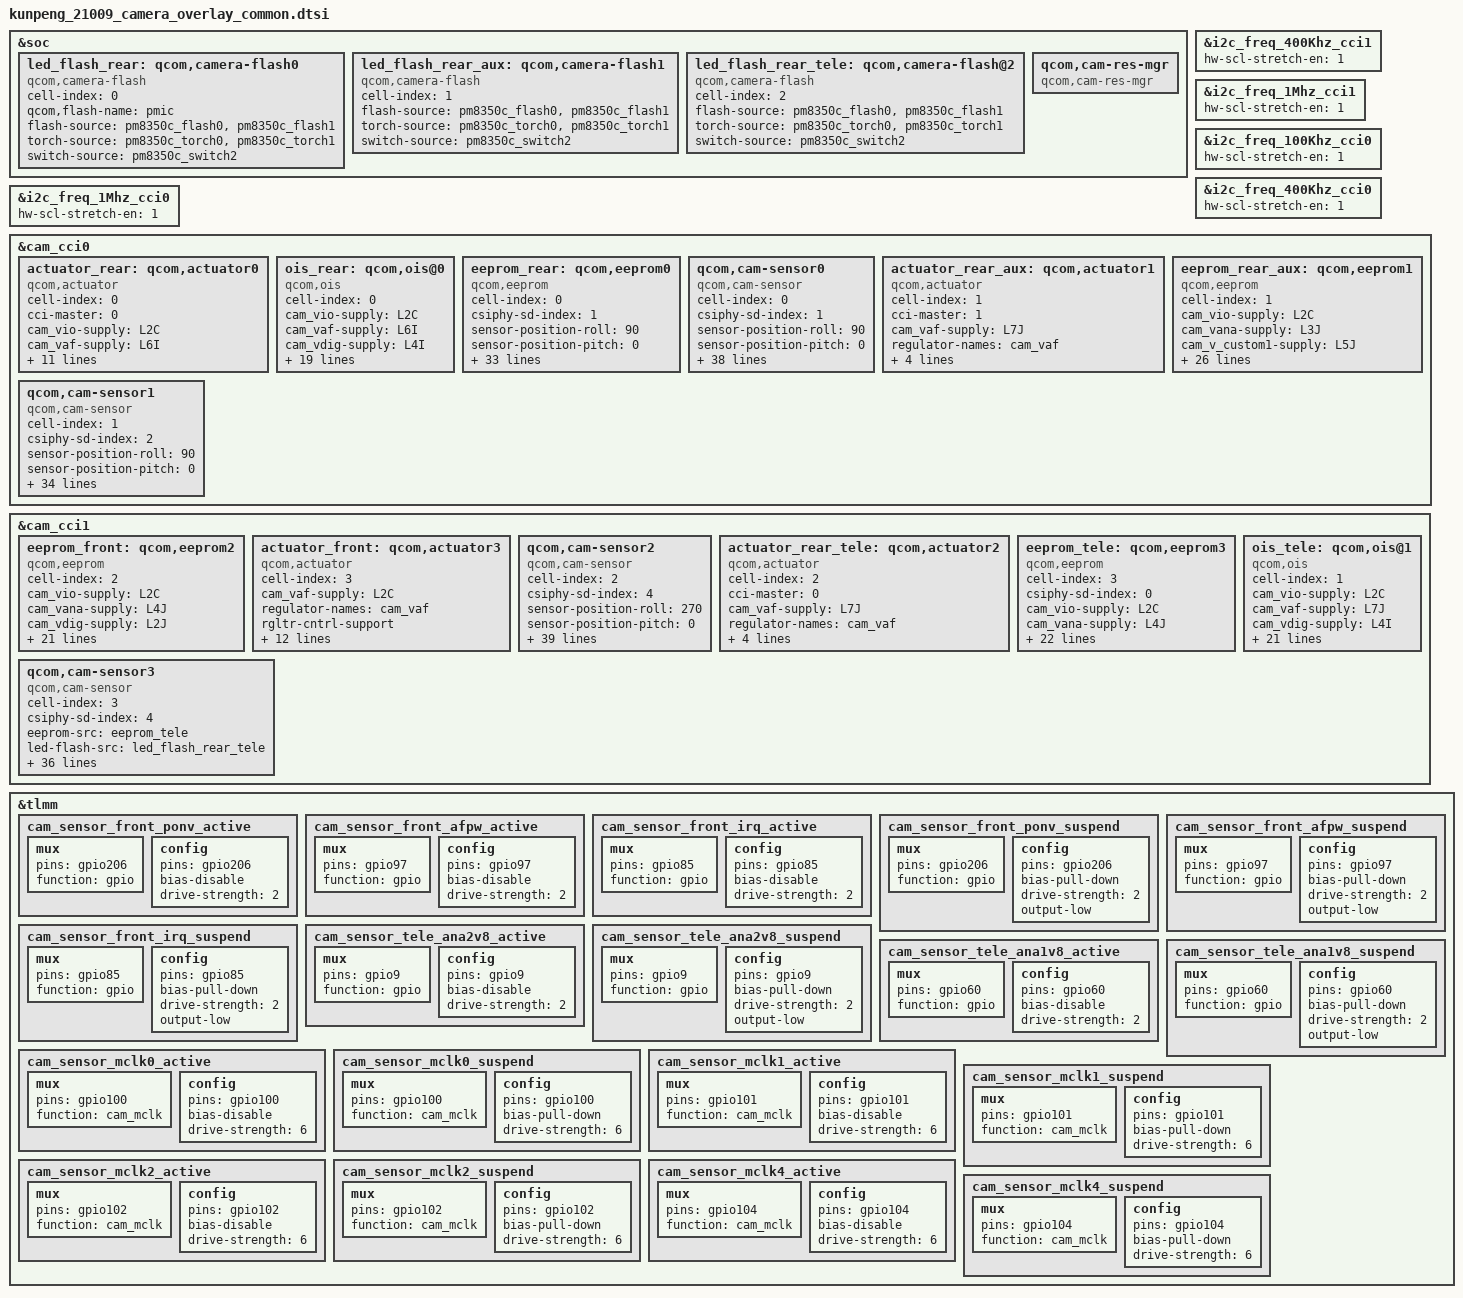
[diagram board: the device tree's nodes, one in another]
#include <dt-bindings/clock/qcom,camcc-waipio.h>
&soc {
	led_flash_rear: qcom,camera-flash0 {
		cell-index = <0>;
		compatible = "qcom,camera-flash";
		qcom,flash-name = "pmic";
		flash-source = <&pm8350c_flash0 &pm8350c_flash1>;
		torch-source = <&pm8350c_torch0 &pm8350c_torch1>;
		switch-source = <&pm8350c_switch2>;
		status = "ok";
	};

	led_flash_rear_aux: qcom,camera-flash1 {
		cell-index = <1>;
		compatible = "qcom,camera-flash";
		flash-source = <&pm8350c_flash0 &pm8350c_flash1>;
		torch-source = <&pm8350c_torch0 &pm8350c_torch1>;
		switch-source = <&pm8350c_switch2>;
		status = "ok";
	};

	led_flash_rear_tele: qcom,camera-flash@2 {
		cell-index = <2>;
		compatible = "qcom,camera-flash";
		flash-source = <&pm8350c_flash0 &pm8350c_flash1>;
		torch-source = <&pm8350c_torch0 &pm8350c_torch1>;
		switch-source = <&pm8350c_switch2>;
		status = "ok";
	};

	qcom,cam-res-mgr {
		compatible = "qcom,cam-res-mgr";
		status = "ok";
	};
};

&i2c_freq_400Khz_cci1 {
    hw-scl-stretch-en = <1>;
};

&i2c_freq_1Mhz_cci1 {
    hw-scl-stretch-en = <1>;
};

&i2c_freq_100Khz_cci0 {
    hw-scl-stretch-en = <1>;
};

&i2c_freq_400Khz_cci0 {
    hw-scl-stretch-en = <1>;
};

&i2c_freq_1Mhz_cci0 {
    hw-scl-stretch-en = <1>;
};

&cam_cci0 {
	actuator_rear: qcom,actuator0 {
		cell-index = <0>;
		compatible = "qcom,actuator";
		cci-master = <0>;
		cam_vio-supply = <&L2C>;
		cam_vaf-supply = <&L6I>;
		cam_vdig-supply = <&L4I>;
		cam_v_custom1-supply = <&L7I>;
		regulator-names = "cam_vio", "cam_vaf","cam_vdig","cam_v_custom1";
		rgltr-cntrl-support;
		rgltr-min-voltage = <1800000 3152000 3152000 1800000>;
		rgltr-max-voltage = <1800000 3304000 3304000 2960000>;
		rgltr-load-current = <300000 300000 600000 700000>;
	};

	ois_rear: qcom,ois@0{
		cell-index = <0>;
		compatible = "qcom,ois";
		cam_vio-supply = <&L2C>;
		cam_vaf-supply = <&L6I>;
		cam_vdig-supply = <&L4I>;
		cam_v_custom1-supply = <&L7I>;
		regulator-names = "cam_vio", "cam_vaf","cam_vdig","cam_v_custom1";
		rgltr-cntrl-support;
		rgltr-min-voltage = <1800000 3152000 3152000 1800000>;
		rgltr-max-voltage = <1800000 3304000 3304000 2960000>;
		rgltr-load-current = <300000 300000 600000 700000>;
		cci-master = <0>;
		ois_gyro,position=<3>;
		ois_gyro,type=<0>;
		ois,type=<0>;
		ois,name="LC898129";
		ois_module,vendor=<0>;
		ois_actuator,vednor=<7>;
		ois,fw=<1>;
		status = "ok";
		ois_eis_function = <3>;
	};
	eeprom_rear: qcom,eeprom0 {
		cell-index = <0>;
		compatible = "qcom,eeprom";
		csiphy-sd-index = <1>;
		sensor-position-roll = <90>;
		sensor-position-pitch = <0>;
		sensor-position-yaw = <180>;
		cam_vio-supply = <&L2C>;
		cam_vana-supply = <&L3I>;
		cam_v_custom1-supply = <&L5I>;
		cam_vdig-supply = <&L1I>;
		cam_vaf-supply = <&L6I>;
		cam_vana1-supply = <&L4I>;
		cam_v_custom2-supply = <&L7I>;
		cam_clk-supply = <&cam_cc_titan_top_gdsc>;
		regulator-names = "cam_vio", "cam_vana", "cam_v_custom1", "cam_vdig", "cam_vaf","cam_vana1","cam_v_custom2",
		"cam_clk";
		rgltr-cntrl-support;
		rgltr-min-voltage = <1800000 2800000 1800000 1160000 3152000 3152000 1800000 0>;
		rgltr-max-voltage = <1800000 2904000 2800000 1204000 3304000 3304000 2960000 0>;
		rgltr-load-current = <300000 300000 300000 1200000 300000 600000 700000 0>;
		gpio-no-mux = <0>;
		pinctrl-names = "cam_default", "cam_suspend";
		pinctrl-0 = <&cam_sensor_mclk1_active
			&cam_sensor_active_rst3>;
		pinctrl-1 = <&cam_sensor_mclk1_suspend
			&cam_sensor_suspend_rst3>;
		gpios = <&tlmm 101 0>,
			<&tlmm 120 0>;
		gpio-reset = <1>;
		gpio-req-tbl-num = <0 1>;
		gpio-req-tbl-flags = <1 0>;
		gpio-req-tbl-label = "CAMIF_MCLK1",
					"CAM_RESET3";
		cci-master = <0>;
		clocks = <&clock_camcc CAM_CC_MCLK1_CLK>;
		clock-names = "cam_clk";
		clock-cntl-level = "nominal";
		clock-rates = <19200000>;
		status = "ok";
	};

	qcom,cam-sensor0 {//main camera
		cell-index = <0>;
		compatible = "qcom,cam-sensor";
		csiphy-sd-index = <1>;
		sensor-position-roll = <90>;
		sensor-position-pitch = <0>;
		sensor-position-yaw = <180>;
		eeprom-src = <&eeprom_rear>;
		actuator-src = <&actuator_rear>;
		led-flash-src = <&led_flash_rear>;
		ois-src = <&ois_rear>;
		cam_vio-supply = <&L2C>;
		cam_vana-supply = <&L3I>;
		cam_v_custom1-supply = <&L5I>;
		cam_vdig-supply = <&L1I>;
		cam_vaf-supply = <&L6I>;
		cam_vana1-supply = <&L4I>;
		cam_v_custom2-supply = <&L7I>;
		cam_clk-supply = <&cam_cc_titan_top_gdsc>;
		regulator-names = "cam_vio", "cam_vana", "cam_v_custom1", "cam_vdig", "cam_vaf","cam_vana1","cam_v_custom2",
		"cam_clk";
		rgltr-cntrl-support;
		rgltr-min-voltage = <1800000 2800000 1800000 1160000 3152000 3152000 1800000 0>;
		rgltr-max-voltage = <1800000 2904000 2800000 1204000 3304000 3304000 2960000 0>;
		rgltr-load-current = <300000 300000 300000 1200000 300000 600000 700000 0>;
		gpio-no-mux = <0>;
		pinctrl-names = "cam_default", "cam_suspend";
		pinctrl-0 = <&cam_sensor_mclk1_active
			&cam_sensor_active_rst3>;
		pinctrl-1 = <&cam_sensor_mclk1_suspend
			&cam_sensor_suspend_rst3>;
		gpios = <&tlmm 101 0>,
			<&tlmm 120 0>;
		gpio-reset = <1>;
		gpio-req-tbl-num = <0 1>;
		gpio-req-tbl-flags = <1 0>;
		gpio-req-tbl-label = "CAMIF_MCLK1",
					"CAM_RESET3";
		cci-master = <0>;
		status = "ok";
		clocks = <&clock_camcc CAM_CC_MCLK1_CLK>;
		clock-names = "cam_clk";
		clock-cntl-level = "nominal";
		clock-rates = <19200000>;
		is-read-eeprom = <1>;
	};

	actuator_rear_aux: qcom,actuator1 {
		cell-index = <1>;
		compatible = "qcom,actuator";
		cci-master = <1>;
		cam_vaf-supply = <&L7J>;
		regulator-names = "cam_vaf";
		rgltr-cntrl-support;
		rgltr-min-voltage = <2800000>;
		rgltr-max-voltage = <3304000>;
		rgltr-load-current = <300000>;
	};

	eeprom_rear_aux: qcom,eeprom1 {
		cell-index = <1>;
		compatible = "qcom,eeprom";
		cam_vio-supply = <&L2C>;
		cam_vana-supply = <&L3J>;
		cam_v_custom1-supply = <&L5J>;
		cam_vaf-supply = <&L6J>;
		cam_vdig-supply = <&L1J>;
		cam_clk-supply = <&cam_cc_titan_top_gdsc>;
		regulator-names = "cam_vio", "cam_vana", "cam_v_custom1", "cam_vaf",
			"cam_vdig", "cam_clk";
		rgltr-cntrl-support;
		rgltr-min-voltage = <1800000 2800000 1800000 2800000 1160000 0>;
		rgltr-max-voltage = <1800000 2904000 2800000 3304000 1204000 0>;
		rgltr-load-current = <300000 300000 300000 300000 1200000 0>;
		gpio-no-mux = <0>;
		pinctrl-names = "cam_default", "cam_suspend";
		pinctrl-0 = <&cam_sensor_mclk2_active
			&cam_sensor_active_rst1>;
		pinctrl-1 = <&cam_sensor_mclk2_suspend
			&cam_sensor_suspend_rst1>;
		gpios = <&tlmm 102 0>,
			<&tlmm 24 0>;
		gpio-reset = <1>;
		gpio-req-tbl-num = <0 1>;
		gpio-req-tbl-flags = <1 0>;
		gpio-req-tbl-label = "CAMIF_MCLK2",
					"CAM_RESET1";
		cci-master = <1>;
		clocks = <&clock_camcc CAM_CC_MCLK2_CLK>;
		clock-names = "cam_clk";
		clock-cntl-level = "turbo";
		clock-rates = <19200000>;
		status = "ok";
	};

	qcom,cam-sensor1 {//wide camera
		cell-index = <1>;
		compatible = "qcom,cam-sensor";
		csiphy-sd-index = <2>;
		sensor-position-roll = <90>;
		sensor-position-pitch = <0>;
		sensor-position-yaw = <180>;
		eeprom-src = <&eeprom_rear_aux>;
		led-flash-src = <&led_flash_rear_aux>;
		actuator-src = <&actuator_rear_aux>;
		cam_vio-supply = <&L2C>;
		cam_vana-supply = <&L3J>;
		cam_v_custom1-supply = <&L5J>;
		cam_vaf-supply = <&L6J>;
		cam_vdig-supply = <&L1J>;
		cam_clk-supply = <&cam_cc_titan_top_gdsc>;
		regulator-names = "cam_vio", "cam_vana", "cam_v_custom1", "cam_vaf",
			"cam_vdig", "cam_clk";
		rgltr-cntrl-support;
		rgltr-min-voltage = <1800000 2800000 1800000 2800000 1160000 0>;
		rgltr-max-voltage = <1800000 2904000 2800000 3304000 1204000 0>;
		rgltr-load-current = <300000 300000 300000 300000 1200000 0>;
		gpio-no-mux = <0>;
		pinctrl-names = "cam_default", "cam_suspend";
		pinctrl-0 = <&cam_sensor_mclk2_active
			&cam_sensor_active_rst1>;
		pinctrl-1 = <&cam_sensor_mclk2_suspend
			&cam_sensor_suspend_rst1>;
		gpios = <&tlmm 102 0>,
			<&tlmm 24 0>;
		gpio-reset = <1>;
		gpio-req-tbl-num = <0 1>;
		gpio-req-tbl-flags = <1 0>;
		gpio-req-tbl-label = "CAMIF_MCLK2",
					"CAM_RESET1";
		cci-master = <1>;
		status = "ok";
		clocks = <&clock_camcc CAM_CC_MCLK2_CLK>;
		clock-names = "cam_clk";
		clock-cntl-level = "turbo";
		clock-rates = <19200000>;
		is-read-eeprom = <1>;
	};
};

&cam_cci1 {
	eeprom_front: qcom,eeprom2 {
		cell-index = <2>;
		compatible = "qcom,eeprom";
		cam_vio-supply = <&L2C>;
		cam_vana-supply = <&L4J>;
		cam_vdig-supply = <&L2J>;
		cam_clk-supply = <&cam_cc_titan_top_gdsc>;
		regulator-names = "cam_vio", "cam_vana",
			"cam_vdig", "cam_clk";
		rgltr-cntrl-support;
		rgltr-min-voltage = <1800000 2904000 810000 0>;
		rgltr-max-voltage = <1800000 3008000 1056000 0>;
		rgltr-load-current = <300000 300000 600000 0>;
		gpio-no-mux = <0>;
		pinctrl-names = "cam_default", "cam_suspend";
		pinctrl-0 = <&cam_sensor_mclk4_active
			&cam_sensor_active_rst6>;
		pinctrl-1 = <&cam_sensor_mclk4_suspend
			&cam_sensor_suspend_rst6>;
		gpios = <&tlmm 104 0>,
			<&tlmm 108 0>;
		gpio-reset = <1>;
		gpio-req-tbl-num = <0 1>;
		gpio-req-tbl-flags = <1 0>;
		gpio-req-tbl-label = "CAMIF_MCLK4",
					"CAM_RESET6";
		cci-master = <1>;
		clocks = <&clock_camcc CAM_CC_MCLK4_CLK>;
		clock-names = "cam_clk";
		clock-cntl-level = "turbo";
		clock-rates = <19200000>;
		status = "ok";
	};
	actuator_front: qcom,actuator3 {
		cell-index = <3>;
		compatible = "qcom,actuator";
		cam_vaf-supply = <&L2C>;
		regulator-names = "cam_vaf";
		rgltr-cntrl-support;
		rgltr-min-voltage = <1800000>;
		rgltr-max-voltage = <1800000>;
		rgltr-load-current = <300000>;
		gpio-no-mux = <0>;
		pinctrl-names = "cam_default", "cam_suspend";
		pinctrl-0 = <&cam_sensor_front_afpw_active>;
		pinctrl-1 = <&cam_sensor_front_afpw_suspend>;
		gpios = <&tlmm 97 0>;
		gpio-af-pwdm = <0>;
		gpio-req-tbl-num = <0>;
		gpio-req-tbl-flags = <0>;
		gpio-req-tbl-label = "CAM_FRONT_AF_PW";
		cci-master = <1>;
	};

	qcom,cam-sensor2 {//front camera
		cell-index = <2>;
		compatible = "qcom,cam-sensor", "zeku,aon-sensor";
		csiphy-sd-index = <4>;
		sensor-position-roll = <270>;
		sensor-position-pitch = <0>;
		sensor-position-yaw = <180>;
		eeprom-src = <&eeprom_front>;
		actuator-src =<&actuator_front>;
		cam_vio-supply = <&L2C>;
		cam_vana-supply = <&L4J>;
		cam_vdig-supply = <&L2J>;
		cam_clk-supply = <&cam_cc_titan_top_gdsc>;
		regulator-names = "cam_vio", "cam_vana",
			"cam_vdig", "cam_clk";
		rgltr-cntrl-support;
		rgltr-min-voltage = <1800000 2904000 810000 0>;
		rgltr-max-voltage = <1800000 3008000 1056000 0>;
		rgltr-load-current = <300000 300000 600000 0>;
		gpio-no-mux = <0>;
		pinctrl-names = "cam_default", "cam_suspend";
		pinctrl-0 = <&cam_sensor_mclk4_active
			&cam_sensor_active_rst6
			&cam_sensor_front_ponv_active
			&cam_sensor_front_irq_active
			&cam_sensor_front_afpw_active>;
		pinctrl-1 = <&cam_sensor_mclk4_suspend
			&cam_sensor_suspend_rst6
			&cam_sensor_front_ponv_suspend
			&cam_sensor_front_irq_suspend
			&cam_sensor_front_afpw_suspend>;
		gpios = <&tlmm 104 0>,
			<&tlmm 108 0>,
			<&tlmm 206 0>,
			<&tlmm  85 0>,
			<&tlmm  97 0>;
		gpio-reset = <1>;
		gpio-custom1 = <2>;
		gpio-custom2 = <3>;
		gpio-af-pwdm = <4>;
		gpio-req-tbl-num = <0 1 2 3 4>;
		gpio-req-tbl-flags = <1 0 0 0 0>;
		gpio-req-tbl-label = "CAMIF_MCLK4",
					"CAM_RESET6",
					"CAM_PONV_FRONT",
					"CAM_IRQ_FRONT",
					"CAM_FRONT_AF_PW";
		cci-master = <1>;
		clocks = <&clock_camcc CAM_CC_MCLK4_CLK>;
		clock-names = "cam_clk";
		clock-cntl-level = "turbo";
		clock-rates = <19200000>;
		status = "ok";
	};

	actuator_rear_tele: qcom,actuator2 {
		cell-index = <2>;
		compatible = "qcom,actuator";
		cci-master = <0>;
		cam_vaf-supply = <&L7J>;
		regulator-names = "cam_vaf";
		rgltr-cntrl-support;
		rgltr-min-voltage = <2800000>;
		rgltr-max-voltage = <2800000>;
		rgltr-load-current = <300000>;
	};

	eeprom_tele: qcom,eeprom3 {
		cell-index = <3>;
		compatible = "qcom,eeprom";
		csiphy-sd-index = <0>;
		cam_vio-supply = <&L2C>;
		cam_vana-supply = <&L4J>;
		cam_vdig-supply = <&L2I>;
		cam_clk-supply = <&cam_cc_titan_top_gdsc>;
		regulator-names = "cam_vio",
			"cam_vdig", "cam_clk";
		rgltr-cntrl-support;
		rgltr-min-voltage = <1800000 1104000 0>;
		rgltr-max-voltage = <1800000 1260000 0>;
		rgltr-load-current = <300000 600000 0>;
		gpio-no-mux = <0>;
		pinctrl-names = "cam_default", "cam_suspend";
		pinctrl-0 = <&cam_sensor_mclk0_active
			&cam_sensor_active_rst0>;
		pinctrl-1 = <&cam_sensor_mclk0_suspend
			&cam_sensor_suspend_rst0>;
		gpios = <&tlmm 100 0>,
			<&tlmm 25 0>;
		gpio-reset = <1>;
		gpio-req-tbl-num = <0 1>;
		gpio-req-tbl-flags = <1 0>;
		gpio-req-tbl-label = "CAMIF_MCLK0",
					"CAM_RESET0";
		sensor-mode = <0>;
		cci-master = <0>;
		status = "ok";
		clocks = <&clock_camcc CAM_CC_MCLK0_CLK>;
		clock-names = "cam_clk";
		clock-cntl-level = "turbo";
		clock-rates = <19200000>;
	};

	ois_tele: qcom,ois@1{
		cell-index = <1>;
		compatible = "qcom,ois";
		cam_vio-supply = <&L2C>;
		cam_vaf-supply = <&L7J>;
		cam_vdig-supply = <&L4I>;
		cam_v_custom1-supply = <&L7I>;
		cam_v_custom2-supply = <&L6I>;
		regulator-names = "cam_vio", "cam_vaf","cam_vdig","cam_v_custom1","cam_v_custom2";
		rgltr-cntrl-support;
		rgltr-min-voltage = <1800000 2800000 3152000 1800000 3152000>;
		rgltr-max-voltage = <1800000 3304000 3304000 2960000 3304000>;
		rgltr-load-current = <300000 300000 600000 700000 300000>;
		cci-master = <0>;
		ois_gyro,position=<3>;
		ois_gyro,type=<0>;
		ois,type=<1>;
		ois,name="bu24721";
		ois_module,vendor=<1>;
		ois_actuator,vednor=<2>;
		ois,fw=<1>;
		download,fw=<1>;
		ois_eis_function = <4>;
		status = "ok";
	};

	qcom,cam-sensor3 {//tele camera
		cell-index = <3>;
		compatible = "qcom,cam-sensor";
		csiphy-sd-index = <4>;
		eeprom-src = <&eeprom_tele>;
		led-flash-src = <&led_flash_rear_tele>;
		actuator-src = <&actuator_rear_tele>;
		ois-src = <&ois_tele>;
		sensor-position-roll = <270>;
		sensor-position-pitch = <0>;
		sensor-position-yaw = <180>;
		cam_vio-supply = <&L2C>;
		cam_vaf-supply = <&L7J>;
		cam_vdig-supply = <&L2I>;
		cam_clk-supply = <&cam_cc_titan_top_gdsc>;
		regulator-names = "cam_vio", "cam_vaf",
			"cam_vdig", "cam_clk";
		rgltr-cntrl-support;
		rgltr-min-voltage = <1800000 2800000 1104000 0>;
		rgltr-max-voltage = <1800000 3304000 1260000 0>;
		rgltr-load-current = <300000 300000 600000 0>;
		gpio-no-mux = <0>;
		pinctrl-names = "cam_default", "cam_suspend";
		pinctrl-0 = <&cam_sensor_mclk0_active
			&cam_sensor_active_rst0
			&cam_sensor_tele_ana2v8_active
			&cam_sensor_tele_ana1v8_active>;
		pinctrl-1 = <&cam_sensor_mclk0_suspend
			&cam_sensor_suspend_rst0
			&cam_sensor_tele_ana2v8_suspend
			&cam_sensor_tele_ana1v8_suspend>;
		gpios = <&tlmm 100 0>,
			<&tlmm 25 0>,
			<&tlmm  9 0>,
			<&tlmm 60 0>;
		gpio-reset = <1>;
		gpio-custom1 = <2>;
		gpio-custom2 = <3>;
		gpio-req-tbl-num = <0 1 2 3>;
		gpio-req-tbl-flags = <1 0 0 0>;
		gpio-req-tbl-label = "CAMIF_MCLK0",
					"CAM_RESET0",
					"CAM_ANA2V8",
					"CAM_ANA1V8";
		cci-master = <0>;
		clocks = <&clock_camcc CAM_CC_MCLK0_CLK>;
		clock-names = "cam_clk";
		clock-cntl-level = "turbo";
		clock-rates = <19200000>;
		status = "ok";
	};
};

&tlmm {
	cam_sensor_front_ponv_active: cam_sensor_front_ponv_active {
		/* RESET */
		mux {
			pins = "gpio206";
			function = "gpio";
		};

		config {
			pins = "gpio206";
			bias-disable; /* No PULL */
			drive-strength = <2>; /* 2 MA */
		};
	};

	cam_sensor_front_afpw_active: cam_sensor_front_afpw_active {
		/* AF PW */
		mux {
			pins = "gpio97";
			function = "gpio";
		};

		config {
			pins = "gpio97";
			bias-disable; /* No PULL */
			drive-strength = <2>; /* 2 MA */
		};
	};
	cam_sensor_front_irq_active: cam_sensor_front_irq_active {
		/* RESET */
		mux {
			pins = "gpio85";
			function = "gpio";
		};

		config {
			pins = "gpio85";
			bias-disable; /* No PULL */
			drive-strength = <2>; /* 2 MA */
		};
	};

	cam_sensor_front_ponv_suspend: cam_sensor_front_ponv_suspend {
		/* RESET */
		mux {
			pins = "gpio206";
			function = "gpio";
		};

		config {
			pins = "gpio206";
			bias-pull-down; /* PULL DOWN */
			drive-strength = <2>; /* 2 MA */
			output-low;
		};
	};
	
	cam_sensor_front_afpw_suspend: cam_sensor_front_afpw_suspend {
		/* RESET */
		mux {
			pins = "gpio97";
			function = "gpio";
		};

		config {
			pins = "gpio97";
			bias-pull-down; /* PULL DOWN */
			drive-strength = <2>; /* 2 MA */
			output-low;
		};
	};

	cam_sensor_front_irq_suspend: cam_sensor_front_irq_suspend {
		/* RESET */
		mux {
			pins = "gpio85";
			function = "gpio";
		};

		config {
			pins = "gpio85";
			bias-pull-down; /* PULL DOWN */
			drive-strength = <2>; /* 2 MA */
			output-low;
		};
	};
	
	
	cam_sensor_tele_ana2v8_active: cam_sensor_tele_ana2v8_active {
		/* AF PW */
		mux {
			pins = "gpio9";
			function = "gpio";
		};

		config {
			pins = "gpio9";
			bias-disable; /* No PULL */
			drive-strength = <2>; /* 2 MA */
		};
	};
	
	cam_sensor_tele_ana2v8_suspend: cam_sensor_tele_ana2v8_suspend {
		/* RESET */
		mux {
			pins = "gpio9";
			function = "gpio";
		};

		config {
			pins = "gpio9";
			bias-pull-down; /* PULL DOWN */
			drive-strength = <2>; /* 2 MA */
			output-low;
		};
	};
	
	cam_sensor_tele_ana1v8_active: cam_sensor_tele_ana1v8_active {
		/* AF PW */
		mux {
			pins = "gpio60";
			function = "gpio";
		};

		config {
			pins = "gpio60";
			bias-disable; /* No PULL */
			drive-strength = <2>; /* 2 MA */
		};
	};
	
	cam_sensor_tele_ana1v8_suspend: cam_sensor_tele_ana1v8_suspend {
		/* RESET */
		mux {
			pins = "gpio60";
			function = "gpio";
		};

		config {
			pins = "gpio60";
			bias-pull-down; /* PULL DOWN */
			drive-strength = <2>; /* 2 MA */
			output-low;
		};
	};

	cam_sensor_mclk0_active: cam_sensor_mclk0_active {
		/* MCLK0 */
		mux {
			pins = "gpio100";
			function = "cam_mclk";
		};

		config {
			pins = "gpio100";
			bias-disable; /* No PULL */
			drive-strength = <6>; /* 2 MA */
		};
	};

	cam_sensor_mclk0_suspend: cam_sensor_mclk0_suspend {
		/* MCLK0 */
		mux {
			pins = "gpio100";
			function = "cam_mclk";
		};

		config {
			pins = "gpio100";
			bias-pull-down; /* PULL DOWN */
			drive-strength = <6>; /* 2 MA */
		};
	};

	cam_sensor_mclk1_active: cam_sensor_mclk1_active {
		/* MCLK1 */
		mux {
			pins = "gpio101";
			function = "cam_mclk";
		};

		config {
			pins = "gpio101";
			bias-disable; /* No PULL */
			drive-strength = <6>; /* 2 MA */
		};
	};

	cam_sensor_mclk1_suspend: cam_sensor_mclk1_suspend {
		/* MCLK1 */
		mux {
			pins = "gpio101";
			function = "cam_mclk";
		};

		config {
			pins = "gpio101";
			bias-pull-down; /* PULL DOWN */
			drive-strength = <6>; /* 2 MA */
		};
	};

	cam_sensor_mclk2_active: cam_sensor_mclk2_active {
		/* MCLK2 */
		mux {
			pins = "gpio102";
			function = "cam_mclk";
		};

		config {
			pins = "gpio102";
			bias-disable; /* No PULL */
			drive-strength = <6>; /* 2 MA */
		};
	};

	cam_sensor_mclk2_suspend: cam_sensor_mclk2_suspend {
		/* MCLK2 */
		mux {
			pins = "gpio102";
			function = "cam_mclk";
		};

		config {
			pins = "gpio102";
			bias-pull-down; /* PULL DOWN */
			drive-strength = <6>; /* 2 MA */
		};
	};

	cam_sensor_mclk4_active: cam_sensor_mclk4_active {
		/* MCLK4 */
		mux {
			pins = "gpio104";
			function = "cam_mclk";
		};

		config {
			pins = "gpio104";
			bias-disable; /* No PULL */
			drive-strength = <6>; /* 2 MA */
		};
	};

	cam_sensor_mclk4_suspend: cam_sensor_mclk4_suspend {
		/* MCLK4 */
		mux {
			pins = "gpio104";
			function = "cam_mclk";
		};

		config {
			pins = "gpio104";
			bias-pull-down; /* PULL DOWN */
			drive-strength = <6>; /* 2 MA */
		};
	};
};
